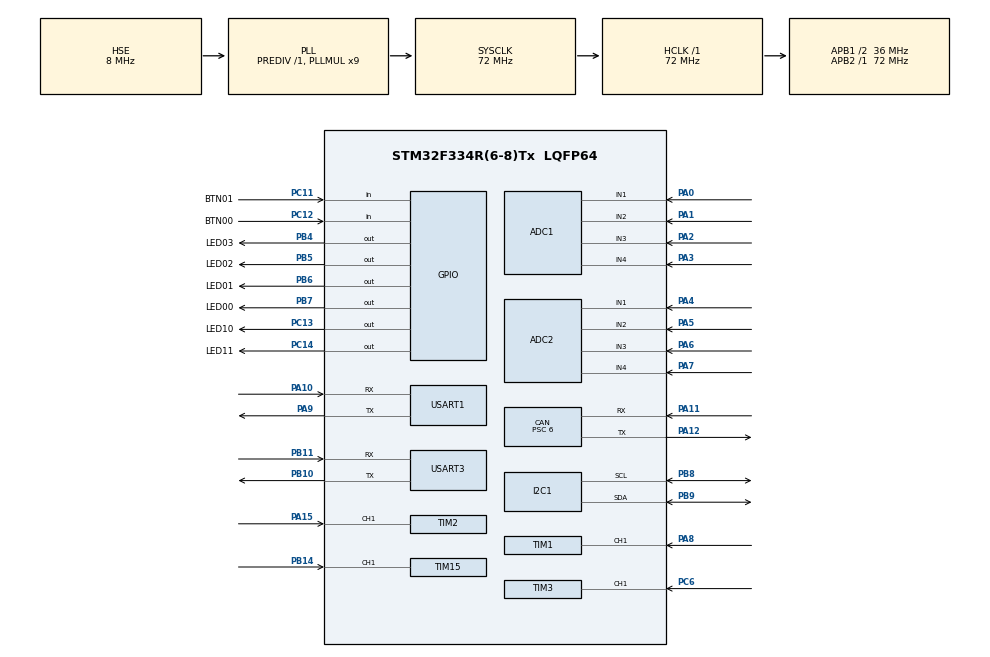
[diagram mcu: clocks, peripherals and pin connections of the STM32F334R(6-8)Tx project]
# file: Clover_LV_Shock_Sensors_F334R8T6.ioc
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ADC1.Channel-0\#ChannelRegularConversion=ADC_CHANNEL_1
ADC1.Channel-5\#ChannelRegularConversion=ADC_CHANNEL_2
ADC1.Channel-6\#ChannelRegularConversion=ADC_CHANNEL_3
ADC1.Channel-7\#ChannelRegularConversion=ADC_CHANNEL_4
ADC1.ClockPrescaler=ADC_CLOCK_SYNC_PCLK_DIV4
ADC1.ContinuousConvMode=ENABLE
ADC1.DMAContinuousRequests=ENABLE
ADC1.EnableInjectedConversion=DISABLE
ADC1.NbrOfConversion=4
ADC1.NbrOfConversionFlag=1
ADC1.Offset-0\#ChannelRegularConversion=0
ADC1.Offset-5\#ChannelRegularConversion=0
ADC1.Offset-6\#ChannelRegularConversion=0
ADC1.Offset-7\#ChannelRegularConversion=0
ADC1.OffsetNumber-0\#ChannelRegularConversion=ADC_OFFSET_NONE
ADC1.OffsetNumber-5\#ChannelRegularConversion=ADC_OFFSET_NONE
ADC1.OffsetNumber-6\#ChannelRegularConversion=ADC_OFFSET_NONE
ADC1.OffsetNumber-7\#ChannelRegularConversion=ADC_OFFSET_NONE
ADC1.Rank-0\#ChannelRegularConversion=1
ADC1.Rank-5\#ChannelRegularConversion=2
ADC1.Rank-6\#ChannelRegularConversion=3
ADC1.Rank-7\#ChannelRegularConversion=4
ADC1.Rank1_Channel=ADC_CHANNEL_1
ADC1.Rank2_Channel=ADC_CHANNEL_1
ADC1.Rank3_Channel=ADC_CHANNEL_1
ADC1.Rank4_Channel=ADC_CHANNEL_1
ADC1.SamplingTime-0\#ChannelRegularConversion=ADC_SAMPLETIME_4CYCLES_5
ADC1.SamplingTime-5\#ChannelRegularConversion=ADC_SAMPLETIME_4CYCLES_5
ADC1.SamplingTime-6\#ChannelRegularConversion=ADC_SAMPLETIME_4CYCLES_5
ADC1.SamplingTime-7\#ChannelRegularConversion=ADC_SAMPLETIME_4CYCLES_5
ADC1.SamplingTimeOPAMP-5\#ChannelRegularConversion=ADC_SAMPLETIME_7CYCLES_5
ADC1.SamplingTimeOPAMP-6\#ChannelRegularConversion=ADC_SAMPLETIME_7CYCLES_5
ADC1.SamplingTimeOPAMP-7\#ChannelRegularConversion=ADC_SAMPLETIME_7CYCLES_5
ADC1.SubFamily=STM32F334x8
ADC1.master=1
ADC2.Channel-1\#ChannelRegularConversion=ADC_CHANNEL_1
ADC2.Channel-2\#ChannelRegularConversion=ADC_CHANNEL_2
ADC2.Channel-3\#ChannelRegularConversion=ADC_CHANNEL_3
ADC2.Channel-4\#ChannelRegularConversion=ADC_CHANNEL_4
ADC2.ClockPrescaler=ADC_CLOCK_SYNC_PCLK_DIV4
ADC2.ContinuousConvMode=ENABLE
ADC2.DMAContinuousRequests=ENABLE
ADC2.EnableInjectedConversion=DISABLE
ADC2.NbrOfConversion=4
ADC2.NbrOfConversionFlag=1
ADC2.Offset-1\#ChannelRegularConversion=0
ADC2.Offset-2\#ChannelRegularConversion=0
ADC2.Offset-3\#ChannelRegularConversion=0
ADC2.Offset-4\#ChannelRegularConversion=0
ADC2.OffsetNumber-1\#ChannelRegularConversion=ADC_OFFSET_NONE
ADC2.OffsetNumber-2\#ChannelRegularConversion=ADC_OFFSET_NONE
ADC2.OffsetNumber-3\#ChannelRegularConversion=ADC_OFFSET_NONE
ADC2.OffsetNumber-4\#ChannelRegularConversion=ADC_OFFSET_NONE
ADC2.Rank-1\#ChannelRegularConversion=1
ADC2.Rank-2\#ChannelRegularConversion=2
ADC2.Rank-3\#ChannelRegularConversion=3
ADC2.Rank-4\#ChannelRegularConversion=4
ADC2.SamplingTime-1\#ChannelRegularConversion=ADC_SAMPLETIME_4CYCLES_5
ADC2.SamplingTime-2\#ChannelRegularConversion=ADC_SAMPLETIME_4CYCLES_5
ADC2.SamplingTime-3\#ChannelRegularConversion=ADC_SAMPLETIME_4CYCLES_5
ADC2.SamplingTime-4\#ChannelRegularConversion=ADC_SAMPLETIME_4CYCLES_5
ADC2.SamplingTimeOPAMP-2\#ChannelRegularConversion=ADC_SAMPLETIME_7CYCLES_5
ADC2.SamplingTimeOPAMP-3\#ChannelRegularConversion=ADC_SAMPLETIME_7CYCLES_5
ADC2.SamplingTimeOPAMP-4\#ChannelRegularConversion=ADC_SAMPLETIME_7CYCLES_5
ADC2.SubFamily=STM32F334x8
CAN.BS1=CAN_BS1_4TQ
CAN.CalculateBaudRate=999999
CAN.CalculateTimeBit=1000
CAN.CalculateTimeQuantum=166.66666666666669
CAN.Prescaler=6
Dma.ADC1.0.Direction=DMA_PERIPH_TO_MEMORY
Dma.ADC1.0.Instance=DMA1_Channel1
Dma.ADC1.0.MemDataAlignment=DMA_MDATAALIGN_WORD
Dma.ADC1.0.MemInc=DMA_MINC_ENABLE
Dma.ADC1.0.Mode=DMA_CIRCULAR
Dma.ADC1.0.PeriphDataAlignment=DMA_PDATAALIGN_WORD
Dma.ADC1.0.PeriphInc=DMA_PINC_DISABLE
Dma.ADC1.0.Priority=DMA_PRIORITY_LOW
Dma.ADC2.1.Direction=DMA_PERIPH_TO_MEMORY
Dma.ADC2.1.Instance=DMA1_Channel2
Dma.ADC2.1.MemDataAlignment=DMA_MDATAALIGN_WORD
Dma.ADC2.1.MemInc=DMA_MINC_ENABLE
Dma.ADC2.1.Mode=DMA_CIRCULAR
Dma.ADC2.1.PeriphDataAlignment=DMA_PDATAALIGN_WORD
Dma.ADC2.1.PeriphInc=DMA_PINC_DISABLE
Dma.ADC2.1.Priority=DMA_PRIORITY_LOW
Dma.Request0=ADC1
Dma.Request1=ADC2
Mcu.Family=STM32F3
Mcu.Name=STM32F334R(6-8)Tx
Mcu.Package=LQFP64
NVIC.CAN_RX0_IRQn=true\:0\:0\:false\:false\:true\:true\:true\:true
NVIC.CAN_RX1_IRQn=true\:0\:0\:false\:false\:true\:true\:true\:true
NVIC.DMA1_Channel1_IRQn=true\:0\:0\:false\:false\:true\:false\:true\:true
NVIC.DMA1_Channel2_IRQn=true\:0\:0\:false\:false\:true\:false\:true\:true
NVIC.PriorityGroup=NVIC_PRIORITYGROUP_4
NVIC.TIM1_BRK_TIM15_IRQn=true\:0\:0\:false\:false\:true\:true\:true\:true
NVIC.TIM2_IRQn=true\:0\:0\:false\:false\:true\:true\:true\:true
NVIC.TIM3_IRQn=true\:0\:0\:false\:false\:true\:true\:true\:true
PA0.Mode=IN1-Single-Ended
PA0.Signal=ADC1_IN1
PA1.Mode=IN2-Single-Ended
PA1.Signal=ADC1_IN2
PA10.Mode=Asynchronous
PA10.Signal=USART1_RX
PA11.Mode=CAN_Activate
PA11.Signal=CAN_RX
PA12.Mode=CAN_Activate
PA12.Signal=CAN_TX
PA13.Mode=Trace_Asynchronous_SW
PA13.Signal=SYS_JTMS-SWDIO
PA14.Mode=Trace_Asynchronous_SW
PA14.Signal=SYS_JTCK-SWCLK
PA15.Signal=S_TIM2_CH1_ETR
PA2.Mode=IN3-Single-Ended
PA2.Signal=ADC1_IN3
PA3.Mode=IN4-Single-Ended
PA3.Signal=ADC1_IN4
PA4.Mode=IN1-Single-Ended
PA4.Signal=ADC2_IN1
PA5.Mode=IN2-Single-Ended
PA5.Signal=ADC2_IN2
PA6.Mode=IN3-Single-Ended
PA6.Signal=ADC2_IN3
PA7.Mode=IN4-Single-Ended
PA7.Signal=ADC2_IN4
PA8.Signal=S_TIM1_CH1
PA9.Mode=Asynchronous
PA9.Signal=USART1_TX
PB10.Mode=Asynchronous
PB10.Signal=USART3_TX
PB11.Mode=Asynchronous
PB11.Signal=USART3_RX
PB14.Signal=S_TIM15_CH1
PB3.Mode=Trace_Asynchronous_SW
PB3.Signal=SYS_JTDO-TRACESWO
PB4.GPIO_Label=LED03
PB4.Signal=GPIO_Output
PB5.GPIO_Label=LED02
PB5.Signal=GPIO_Output
PB6.GPIO_Label=LED01
PB6.Signal=GPIO_Output
PB7.GPIO_Label=LED00
PB7.Signal=GPIO_Output
PB8.Mode=I2C
PB8.Signal=I2C1_SCL
PB9.Mode=I2C
PB9.Signal=I2C1_SDA
PC11.GPIO_Label=BTN01
PC11.Signal=GPIO_Input
PC12.GPIO_Label=BTN00
PC12.Signal=GPIO_Input
PC13.GPIO_Label=LED10
PC13.Signal=GPIO_Output
PC14\ /\ OSC32_IN.GPIO_Label=LED11
PC14\ /\ OSC32_IN.Signal=GPIO_Output
PC6.Signal=S_TIM3_CH1
PF0\ /\ OSC_IN.Mode=HSE-External-Oscillator
PF0\ /\ OSC_IN.Signal=RCC_OSC_IN
PF1\ /\ OSC_OUT.Mode=HSE-External-Oscillator
PF1\ /\ OSC_OUT.Signal=RCC_OSC_OUT
ProjectManager.HeapSize=0x200
ProjectManager.StackSize=0x400
ProjectManager.TargetToolchain=STM32CubeIDE
RCC.AHBFreq_Value=72000000
RCC.APB1CLKDivider=RCC_HCLK_DIV2
RCC.APB1Freq_Value=36000000
RCC.APB1TimFreq_Value=72000000
RCC.APB2Freq_Value=72000000
RCC.APB2TimFreq_Value=72000000
RCC.CortexFreq_Value=72000000
RCC.HCLKFreq_Value=72000000
RCC.HSE_VALUE=8000000
RCC.HSI_VALUE=8000000
RCC.LSE_VALUE=32768
RCC.PLLMUL=RCC_PLL_MUL9
RCC.PLLSourceVirtual=RCC_PLLSOURCE_HSE
RCC.SYSCLKFreq_VALUE=72000000
RCC.SYSCLKSourceVirtual=RCC_SYSCLKSOURCE_PLLCLK
SH.S_TIM15_CH1.0=TIM15_CH1,PWM_Input_1
SH.S_TIM1_CH1.0=TIM1_CH1,PWM_Input_1
SH.S_TIM2_CH1_ETR.0=TIM2_CH1,PWM_Input_1
SH.S_TIM3_CH1.0=TIM3_CH1,PWM_Input_1
TIM15.Prescaler=288-1
TIM2.Prescaler=72 - 1
TIM3.Prescaler=288 - 1
USART1.VirtualMode-Asynchronous=VM_ASYNC
USART3.VirtualMode-Asynchronous=VM_ASYNC
VP_IWDG_VS_IWDG.Mode=IWDG_Activate
VP_TIM15_VS_ClockSourceINT.Mode=Internal
VP_TIM1_VS_ClockSourceINT.Mode=Internal
VP_TIM2_VS_ClockSourceINT.Mode=Internal
VP_TIM3_VS_ClockSourceINT.Mode=Internal
board=custom

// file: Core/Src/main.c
/* USER CODE BEGIN Header */
/**
  ******************************************************************************
  * @file           : main.c
  * @brief          : Main program body
  ******************************************************************************
  * @attention
  *
  * <h2><center>&copy; Copyright (c) 2023 STMicroelectronics.
  * All rights reserved.</center></h2>
  *
  * This software component is licensed by ST under BSD 3-Clause license,
  * the "License"; You may not use this file except in compliance with the
  * License. You may obtain a copy of the License at:
  *                        opensource.org/licenses/BSD-3-Clause
  *
  ******************************************************************************
  */
/* USER CODE END Header */
#include "main.h"
#include "adc.h"
#include "can.h"
#include "dma.h"
#include "i2c.h"
#include "iwdg.h"
#include "tim.h"
#include "usart.h"
#include "gpio.h"

/* USER CODE BEGIN Includes */
#include "GAS_Scheduler.h"
/* USER CODE END Includes */

void SystemClock_Config(void);

/* USER CODE BEGIN 0 */
void HAL_TIM_IC_CaptureCallback(TIM_HandleTypeDef *htim) {
	GAS_Pwm_InterruptServiceRoutine(htim);
}

/* USER CODE END 0 */

int main(void)
{

  /* MCU Configuration--------------------------------------------------------*/

  /* Reset of all peripherals, Initializes the Flash interface and the Systick. */
  HAL_Init();

  /* Configure the system clock */
  SystemClock_Config();

  /* Initialize all configured peripherals */
  MX_GPIO_Init();
  MX_DMA_Init();
  MX_ADC1_Init();
  MX_ADC2_Init();
  MX_CAN_Init();
  MX_I2C1_Init();
  MX_TIM1_Init();
  MX_TIM2_Init();
  MX_TIM3_Init();
  MX_TIM15_Init();
  MX_USART1_UART_Init();
  MX_USART3_UART_Init();
  MX_IWDG_Init();
  /* USER CODE BEGIN 2 */
  GAS_Scheduler_init();
  /* USER CODE END 2 */

  /* Infinite loop */
  while (1)
  {

    /* USER CODE BEGIN 3 */
	  //HAL_GPIO_TogglePin(GPIOB, LED00_Pin);
	  //HAL_Delay(100);
	  GAS_Scheduler();
	  HAL_IWDG_Refresh(&hiwdg);
  }
  /* USER CODE END 3 */
}

void SystemClock_Config(void)
{
  RCC_OscInitTypeDef RCC_OscInitStruct = {0};
  RCC_ClkInitTypeDef RCC_ClkInitStruct = {0};
  RCC_PeriphCLKInitTypeDef PeriphClkInit = {0};

  /** Initializes the RCC Oscillators according to the specified parameters
  * in the RCC_OscInitTypeDef structure.
  */
  RCC_OscInitStruct.OscillatorType = RCC_OSCILLATORTYPE_HSI|RCC_OSCILLATORTYPE_LSI
                              |RCC_OSCILLATORTYPE_HSE;
  RCC_OscInitStruct.HSEState = RCC_HSE_ON;
  RCC_OscInitStruct.HSEPredivValue = RCC_HSE_PREDIV_DIV1;
  RCC_OscInitStruct.HSIState = RCC_HSI_ON;
  RCC_OscInitStruct.HSICalibrationValue = RCC_HSICALIBRATION_DEFAULT;
  RCC_OscInitStruct.LSIState = RCC_LSI_ON;
  RCC_OscInitStruct.PLL.PLLState = RCC_PLL_ON;
  RCC_OscInitStruct.PLL.PLLSource = RCC_PLLSOURCE_HSE;
  RCC_OscInitStruct.PLL.PLLMUL = RCC_PLL_MUL9;
  if (HAL_RCC_OscConfig(&RCC_OscInitStruct) != HAL_OK)
  {
    Error_Handler();
  }
  /** Initializes the CPU, AHB and APB buses clocks
  */
  RCC_ClkInitStruct.ClockType = RCC_CLOCKTYPE_HCLK|RCC_CLOCKTYPE_SYSCLK
                              |RCC_CLOCKTYPE_PCLK1|RCC_CLOCKTYPE_PCLK2;
  RCC_ClkInitStruct.SYSCLKSource = RCC_SYSCLKSOURCE_PLLCLK;
  RCC_ClkInitStruct.AHBCLKDivider = RCC_SYSCLK_DIV1;
  RCC_ClkInitStruct.APB1CLKDivider = RCC_HCLK_DIV2;
  RCC_ClkInitStruct.APB2CLKDivider = RCC_HCLK_DIV1;

  if (HAL_RCC_ClockConfig(&RCC_ClkInitStruct, FLASH_LATENCY_2) != HAL_OK)
  {
    Error_Handler();
  }
  PeriphClkInit.PeriphClockSelection = RCC_PERIPHCLK_USART1|RCC_PERIPHCLK_I2C1
                              |RCC_PERIPHCLK_TIM1;
  PeriphClkInit.Usart1ClockSelection = RCC_USART1CLKSOURCE_PCLK1;
  PeriphClkInit.I2c1ClockSelection = RCC_I2C1CLKSOURCE_HSI;
  PeriphClkInit.Tim1ClockSelection = RCC_TIM1CLK_HCLK;
  if (HAL_RCCEx_PeriphCLKConfig(&PeriphClkInit) != HAL_OK)
  {
    Error_Handler();
  }
}

void Error_Handler(void)
{
  __disable_irq();
  while (1)
  {
  }
}

/************************ (C) COPYRIGHT STMicroelectronics *****END OF FILE****/
